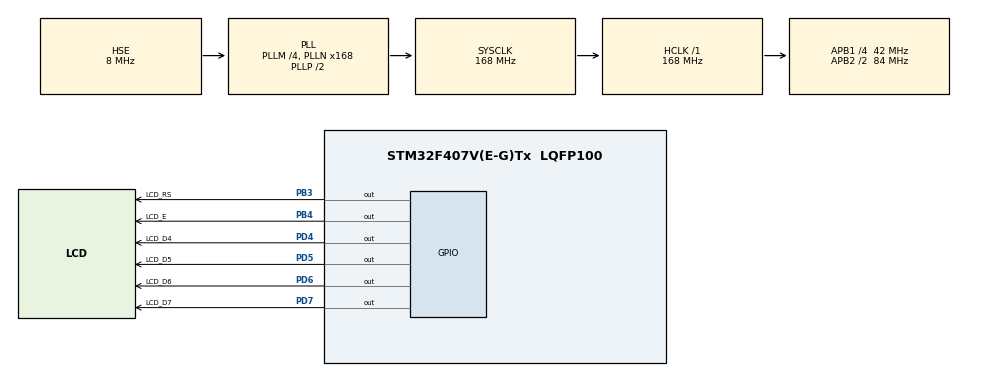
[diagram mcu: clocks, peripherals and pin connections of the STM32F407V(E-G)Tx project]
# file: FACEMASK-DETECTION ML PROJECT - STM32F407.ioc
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Mcu.Family=STM32F4
Mcu.Name=STM32F407V(E-G)Tx
Mcu.Package=LQFP100
NVIC.PriorityGroup=NVIC_PRIORITYGROUP_0
PB3.GPIO_Label=LCD_RS
PB3.GPIO_Speed=GPIO_SPEED_FREQ_MEDIUM
PB3.Signal=GPIO_Output
PB4.GPIO_Label=LCD_E
PB4.GPIO_Speed=GPIO_SPEED_FREQ_MEDIUM
PB4.Signal=GPIO_Output
PD4.GPIO_Label=LCD_D4
PD4.GPIO_Speed=GPIO_SPEED_FREQ_MEDIUM
PD4.Signal=GPIO_Output
PD5.GPIO_Label=LCD_D5
PD5.GPIO_Speed=GPIO_SPEED_FREQ_MEDIUM
PD5.Signal=GPIO_Output
PD6.GPIO_Label=LCD_D6
PD6.GPIO_Speed=GPIO_SPEED_FREQ_MEDIUM
PD6.Signal=GPIO_Output
PD7.GPIO_Label=LCD_D7
PD7.GPIO_Speed=GPIO_SPEED_FREQ_MEDIUM
PD7.Signal=GPIO_Output
PH0-OSC_IN.Mode=HSE-External-Oscillator
PH0-OSC_IN.Signal=RCC_OSC_IN
PH1-OSC_OUT.Mode=HSE-External-Oscillator
PH1-OSC_OUT.Signal=RCC_OSC_OUT
ProjectManager.HeapSize=0x200
ProjectManager.StackSize=0x1000
ProjectManager.TargetToolchain=STM32CubeIDE
RCC.48MHZClocksFreq_Value=48000000
RCC.AHBFreq_Value=168000000
RCC.APB1CLKDivider=RCC_HCLK_DIV4
RCC.APB1Freq_Value=42000000
RCC.APB1TimFreq_Value=84000000
RCC.APB2CLKDivider=RCC_HCLK_DIV2
RCC.APB2Freq_Value=84000000
RCC.APB2TimFreq_Value=168000000
RCC.CortexFreq_Value=168000000
RCC.HCLKFreq_Value=168000000
RCC.HSE_VALUE=8000000
RCC.HSI_VALUE=16000000
RCC.PLLM=4
RCC.PLLN=168
RCC.PLLQ=7
RCC.PLLSourceVirtual=RCC_PLLSOURCE_HSE
RCC.SYSCLKFreq_VALUE=168000000
RCC.SYSCLKSource=RCC_SYSCLKSOURCE_PLLCLK
RCC.VCOOutputFreq_Value=336000000
STMicroelectronics.X-CUBE-AI.6.0.0.ActivationBufferSizeList=42208
STMicroelectronics.X-CUBE-AI.6.0.0.HeapSize=0x200
STMicroelectronics.X-CUBE-AI.6.0.0.InternalRamActivationBufferMaxSize=AI_FACEMASKDETECTIONSTM32F407TFLITE_DATA_ACTIVATIONS_SIZE
STMicroelectronics.X-CUBE-AI.6.0.0.LatestDirectoryUsed-84df728f35ec7469813d7ee03e3c0b12d913501093f6d2f1ce465674b7c8a062=C\:\\Users\\shubh\\anaconda3\\envs\\FACEMASK DETECTION - STM32F407
STMicroelectronics.X-CUBE-AI.6.0.0.MaximumNumberOfInputLayer=1
STMicroelectronics.X-CUBE-AI.6.0.0.MaximumNumberOfOutputLayer=1
STMicroelectronics.X-CUBE-AI.6.0.0.MaximumSizeOfInputLayer=AI_FACEMASKDETECTIONSTM32F407TFLITE_IN_1_SIZE_BYTES
STMicroelectronics.X-CUBE-AI.6.0.0.MaximumSizeOfOutputLayer=AI_FACEMASKDETECTIONSTM32F407TFLITE_OUT_1_SIZE_BYTES
STMicroelectronics.X-CUBE-AI.6.0.0.ModelActualCompression-84df728f35ec7469813d7ee03e3c0b12d913501093f6d2f1ce465674b7c8a062=1.0157338
STMicroelectronics.X-CUBE-AI.6.0.0.ModelCompression-84df728f35ec7469813d7ee03e3c0b12d913501093f6d2f1ce465674b7c8a062=8
STMicroelectronics.X-CUBE-AI.6.0.0.ModelFlashOccupation-84df728f35ec7469813d7ee03e3c0b12d913501093f6d2f1ce465674b7c8a062=33368
STMicroelectronics.X-CUBE-AI.6.0.0.ModelHashList=84df728f35ec7469813d7ee03e3c0b12d913501093f6d2f1ce465674b7c8a062
STMicroelectronics.X-CUBE-AI.6.0.0.ModelKind-84df728f35ec7469813d7ee03e3c0b12d913501093f6d2f1ce465674b7c8a062=TFLITE
STMicroelectronics.X-CUBE-AI.6.0.0.ModelMacc-84df728f35ec7469813d7ee03e3c0b12d913501093f6d2f1ce465674b7c8a062=1997212
STMicroelectronics.X-CUBE-AI.6.0.0.ModelName-84df728f35ec7469813d7ee03e3c0b12d913501093f6d2f1ce465674b7c8a062=facemaskdetectionstm32f407tflite
STMicroelectronics.X-CUBE-AI.6.0.0.ModelNameList=facemaskdetectionstm32f407tflite
STMicroelectronics.X-CUBE-AI.6.0.0.ModelRamOccupation-84df728f35ec7469813d7ee03e3c0b12d913501093f6d2f1ce465674b7c8a062=42208
STMicroelectronics.X-CUBE-AI.6.0.0.ModelStructureFile-84df728f35ec7469813d7ee03e3c0b12d913501093f6d2f1ce465674b7c8a062=C\:\\Users\\shubh\\anaconda3\\envs\\FACEMASK DETECTION - STM32F407\\tf_lite_model.tflite
STMicroelectronics.X-CUBE-AI.6.0.0.ModelType-84df728f35ec7469813d7ee03e3c0b12d913501093f6d2f1ce465674b7c8a062=STM32Cube.AI runtime
STMicroelectronics.X-CUBE-AI.6.0.0.StackSize=0x1000
STMicroelectronics.X-CUBE-AI.6.0.0.WorkingBufferStartAddrList=0xFFFFFFFF
STMicroelectronics.X-CUBE-AI.6.0.0.XAaCUBEAaAICcArtificialOoIntelligenceJjCore=true
VP_CRC_VS_CRC.Mode=CRC_Activate
VP_STMicroelectronics.X-CUBE-AI_VS_ArtificialOoIntelligenceJjXAaCUBEAaAI_6.0.0.Mode=ArtificialOoIntelligenceJjXAaCUBEAaAI
board=STM32F407G-DISC1

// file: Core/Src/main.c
/* USER CODE BEGIN Header */
/**
  ******************************************************************************
  * @file           : main.c
  * @brief          : Main program body
  ******************************************************************************
  * @attention
  *
  * <h2><center>&copy; Copyright (c) 2021 STMicroelectronics.
  * All rights reserved.</center></h2>
  *
  * This software component is licensed by ST under Ultimate Liberty license
  * SLA0044, the "License"; You may not use this file except in compliance with
  * the License. You may obtain a copy of the License at:
  *                             www.st.com/SLA0044
  *
  ******************************************************************************
  */
/* USER CODE END Header */
#include "main.h"

/* USER CODE BEGIN Includes */
#include "lcd16x2.h"  // For LCD screen
/* USER CODE END Includes */

CRC_HandleTypeDef hcrc;

void SystemClock_Config(void);
static void MX_GPIO_Init(void);
static void MX_CRC_Init(void);

int main(void)
{

  /* MCU Configuration--------------------------------------------------------*/

  /* Reset of all peripherals, Initializes the Flash interface and the Systick. */
  HAL_Init();

  /* Configure the system clock */
  SystemClock_Config();

  /* Initialize all configured peripherals */
  MX_GPIO_Init();
  MX_CRC_Init();
  /* USER CODE BEGIN 2 */

  //-----------------   LCD CODE-------------------
  lcd16x2_init_4bits(LCD_RS_GPIO_Port, LCD_RS_Pin, LCD_E_Pin,
		  	  	  	 LCD_D4_GPIO_Port, LCD_D4_Pin, LCD_D5_Pin, LCD_D6_Pin, LCD_D7_Pin);   // LCD initialize

  for (int i = 0; i <= 16; i++)                               // "PHYSICS PROJECT" scrolling right
  {
	  lcd16x2_setCursor(0,0);
	  lcd16x2_printf("MINI PROJECT-2B");
	  lcd16x2_shiftRight(1);
	  HAL_Delay(200);
  }

  lcd16x2_setCursor(0,1);
  lcd16x2_printf("GROUP: 1");
  HAL_Delay(1000);

  lcd16x2_clear();

  /* USER CODE END 2 */

  /* Infinite loop */
  while (1)
  {

  }
}

void SystemClock_Config(void)
{
  RCC_OscInitTypeDef RCC_OscInitStruct = {0};
  RCC_ClkInitTypeDef RCC_ClkInitStruct = {0};

  /** Configure the main internal regulator output voltage
  */
  __HAL_RCC_PWR_CLK_ENABLE();
  __HAL_PWR_VOLTAGESCALING_CONFIG(PWR_REGULATOR_VOLTAGE_SCALE1);
  /** Initializes the RCC Oscillators according to the specified parameters
  * in the RCC_OscInitTypeDef structure.
  */
  RCC_OscInitStruct.OscillatorType = RCC_OSCILLATORTYPE_HSE;
  RCC_OscInitStruct.HSEState = RCC_HSE_ON;
  RCC_OscInitStruct.PLL.PLLState = RCC_PLL_ON;
  RCC_OscInitStruct.PLL.PLLSource = RCC_PLLSOURCE_HSE;
  RCC_OscInitStruct.PLL.PLLM = 4;
  RCC_OscInitStruct.PLL.PLLN = 168;
  RCC_OscInitStruct.PLL.PLLP = RCC_PLLP_DIV2;
  RCC_OscInitStruct.PLL.PLLQ = 7;
  if (HAL_RCC_OscConfig(&RCC_OscInitStruct) != HAL_OK)
  {
    Error_Handler();
  }
  /** Initializes the CPU, AHB and APB buses clocks
  */
  RCC_ClkInitStruct.ClockType = RCC_CLOCKTYPE_HCLK|RCC_CLOCKTYPE_SYSCLK
                              |RCC_CLOCKTYPE_PCLK1|RCC_CLOCKTYPE_PCLK2;
  RCC_ClkInitStruct.SYSCLKSource = RCC_SYSCLKSOURCE_PLLCLK;
  RCC_ClkInitStruct.AHBCLKDivider = RCC_SYSCLK_DIV1;
  RCC_ClkInitStruct.APB1CLKDivider = RCC_HCLK_DIV4;
  RCC_ClkInitStruct.APB2CLKDivider = RCC_HCLK_DIV2;

  if (HAL_RCC_ClockConfig(&RCC_ClkInitStruct, FLASH_LATENCY_5) != HAL_OK)
  {
    Error_Handler();
  }
}

static void MX_CRC_Init(void)
{

  hcrc.Instance = CRC;
  if (HAL_CRC_Init(&hcrc) != HAL_OK)
  {
    Error_Handler();
  }

}

static void MX_GPIO_Init(void)
{
  GPIO_InitTypeDef GPIO_InitStruct = {0};

  /* GPIO Ports Clock Enable */
  __HAL_RCC_GPIOH_CLK_ENABLE();
  __HAL_RCC_GPIOD_CLK_ENABLE();
  __HAL_RCC_GPIOB_CLK_ENABLE();

  /*Configure GPIO pin Output Level */
  HAL_GPIO_WritePin(GPIOD, LCD_D4_Pin|LCD_D5_Pin|LCD_D6_Pin|LCD_D7_Pin, GPIO_PIN_RESET);

  /*Configure GPIO pin Output Level */
  HAL_GPIO_WritePin(GPIOB, LCD_RS_Pin|LCD_E_Pin, GPIO_PIN_RESET);

  /*Configure GPIO pins : LCD_D4_Pin LCD_D5_Pin LCD_D6_Pin LCD_D7_Pin */
  GPIO_InitStruct.Pin = LCD_D4_Pin|LCD_D5_Pin|LCD_D6_Pin|LCD_D7_Pin;
  GPIO_InitStruct.Mode = GPIO_MODE_OUTPUT_PP;
  GPIO_InitStruct.Pull = GPIO_NOPULL;
  GPIO_InitStruct.Speed = GPIO_SPEED_FREQ_MEDIUM;
  HAL_GPIO_Init(GPIOD, &GPIO_InitStruct);

  /*Configure GPIO pins : LCD_RS_Pin LCD_E_Pin */
  GPIO_InitStruct.Pin = LCD_RS_Pin|LCD_E_Pin;
  GPIO_InitStruct.Mode = GPIO_MODE_OUTPUT_PP;
  GPIO_InitStruct.Pull = GPIO_NOPULL;
  GPIO_InitStruct.Speed = GPIO_SPEED_FREQ_MEDIUM;
  HAL_GPIO_Init(GPIOB, &GPIO_InitStruct);

}

void Error_Handler(void)
{
  __disable_irq();
  while (1)
  {
  }
}

/************************ (C) COPYRIGHT STMicroelectronics *****END OF FILE****/
